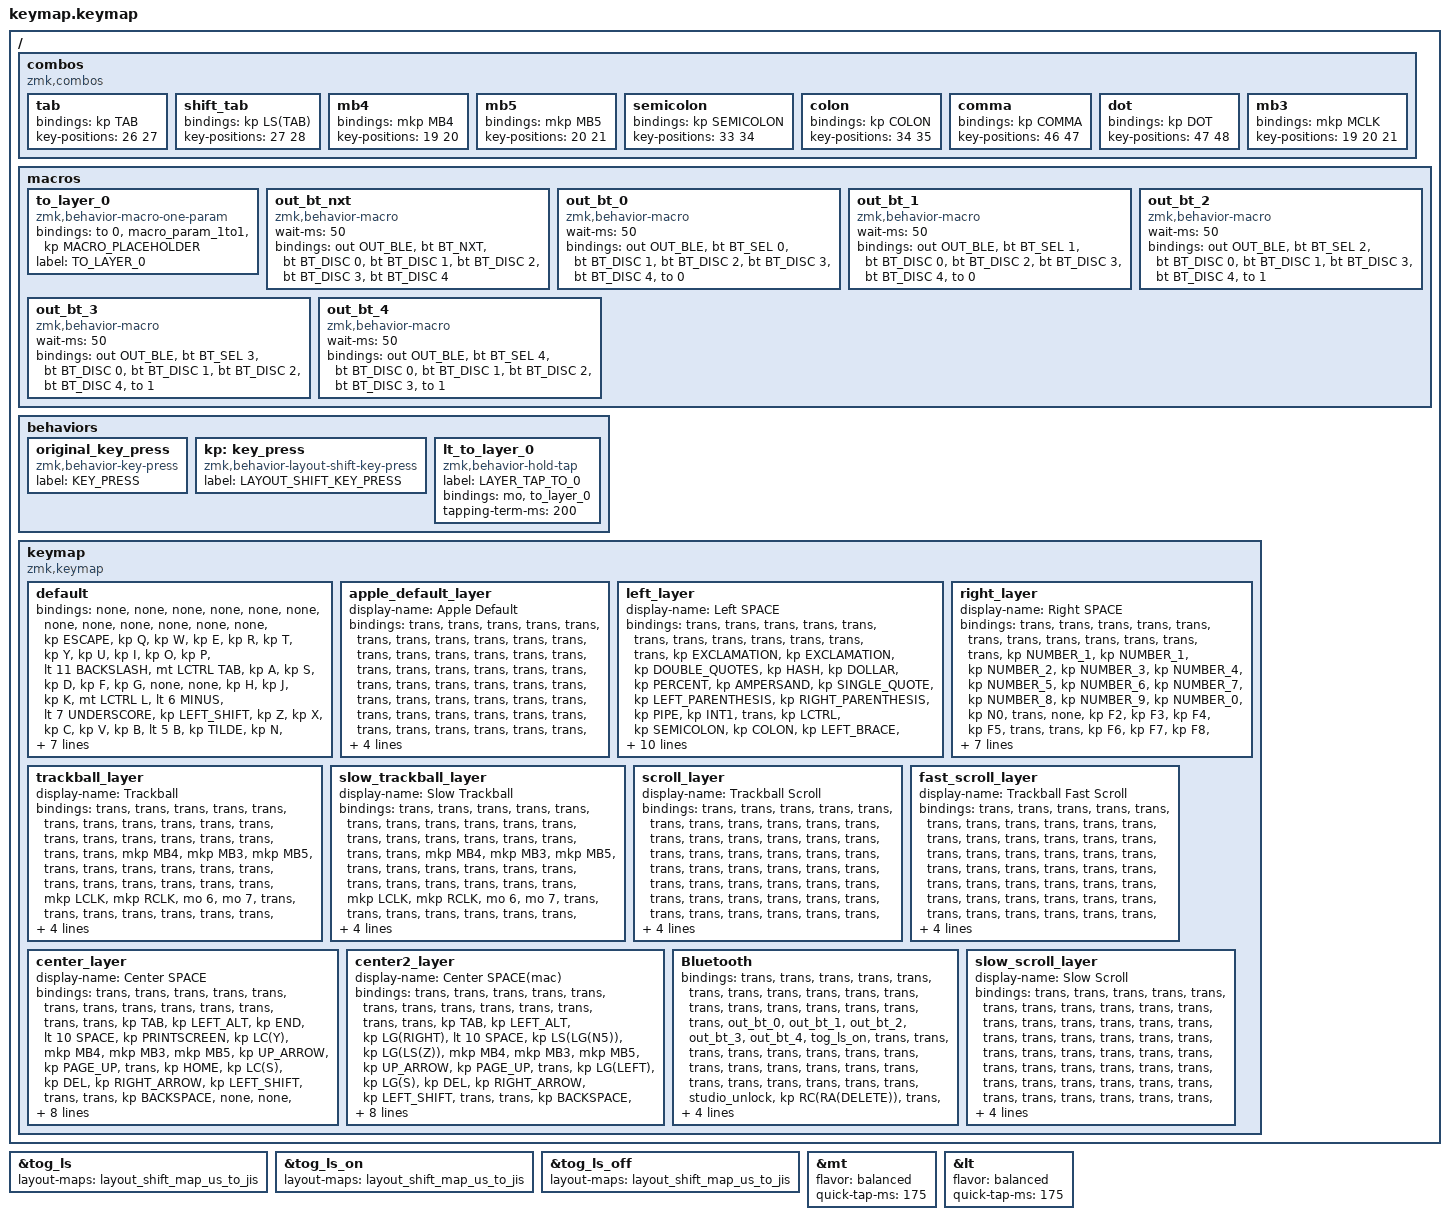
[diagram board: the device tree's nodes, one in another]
// Layer definitions

#include "layers.dtsi"

// ZMK Layout Shiftモジュール(https://github.com/kot149/zmk-layout-shift/blob/v2/README_ja.md)を使う
// US配列のキーコードをJIS配列OS向けに変換する(&kpの上書きはKeymapEditor対策としてbehaviors内で直接定義)

#include <layout_shift.dtsi>
#include <behaviors.dtsi>
#include <dt-bindings/zmk/bt.h>
#include <dt-bindings/zmk/keys.h>
#include <dt-bindings/zmk/outputs.h>
#include <dt-bindings/zmk/pointing.h>

&tog_ls { layout-maps = <&layout_shift_map_us_to_jis>; };
&tog_ls_on { layout-maps = <&layout_shift_map_us_to_jis>; };
&tog_ls_off { layout-maps = <&layout_shift_map_us_to_jis>; };

&mt {
    flavor = "balanced";
    quick-tap-ms = <175>;
};

&lt {
    flavor = "balanced";
    quick-tap-ms = <175>;
};

/ {
    combos {
        compatible = "zmk,combos";

        tab {
            bindings = <&kp TAB>;
            key-positions = <26 27>;
        };

        shift_tab {
            bindings = <&kp LS(TAB)>;
            key-positions = <27 28>;
        };

        mb4 {
            bindings = <&mkp MB4>;
            key-positions = <19 20>;
        };

        mb5 {
            bindings = <&mkp MB5>;
            key-positions = <20 21>;
        };

        semicolon {
            bindings = <&kp SEMICOLON>;
            key-positions = <33 34>;
        };

        colon {
            bindings = <&kp COLON>;
            key-positions = <34 35>;
        };

        comma {
            bindings = <&kp COMMA>;
            key-positions = <46 47>;
        };

        dot {
            bindings = <&kp DOT>;
            key-positions = <47 48>;
        };

        mb3 {
            bindings = <&mkp MCLK>;
            key-positions = <19 20 21>;
        };
    };

    macros {
        to_layer_0: to_layer_0 {
            compatible = "zmk,behavior-macro-one-param";
            #binding-cells = <1>;
            bindings = <&to 0 &macro_param_1to1 &kp MACRO_PLACEHOLDER>;
            label = "TO_LAYER_0";
        };

        // Disconnect from all once for reliable connection to selected profile.
        // ZMK automatically reconnects to current profile right after disconnection.

        out_bt_nxt: out_bt_nxt {
            compatible = "zmk,behavior-macro";
            #binding-cells = <0>;
            wait-ms = <50>;
            bindings = <&out OUT_BLE &bt BT_NXT &bt BT_DISC 0 &bt BT_DISC 1 &bt BT_DISC 2 &bt BT_DISC 3 &bt BT_DISC 4>;
        };

        // Select specific BT device (0-4), disconnect others, and switch to the
        // default layer matching that device's OS (0-1: Windows, 2-4: Apple)

        out_bt_0: out_bt_0 {
            compatible = "zmk,behavior-macro";
            #binding-cells = <0>;
            wait-ms = <50>;
            bindings = <&out OUT_BLE &bt BT_SEL 0 &bt BT_DISC 1 &bt BT_DISC 2 &bt BT_DISC 3 &bt BT_DISC 4 &to 0>;
        };

        out_bt_1: out_bt_1 {
            compatible = "zmk,behavior-macro";
            #binding-cells = <0>;
            wait-ms = <50>;
            bindings = <&out OUT_BLE &bt BT_SEL 1 &bt BT_DISC 0 &bt BT_DISC 2 &bt BT_DISC 3 &bt BT_DISC 4 &to 0>;
        };

        out_bt_2: out_bt_2 {
            compatible = "zmk,behavior-macro";
            #binding-cells = <0>;
            wait-ms = <50>;
            bindings = <&out OUT_BLE &bt BT_SEL 2 &bt BT_DISC 0 &bt BT_DISC 1 &bt BT_DISC 3 &bt BT_DISC 4 &to 1>;
        };

        out_bt_3: out_bt_3 {
            compatible = "zmk,behavior-macro";
            #binding-cells = <0>;
            wait-ms = <50>;
            bindings = <&out OUT_BLE &bt BT_SEL 3 &bt BT_DISC 0 &bt BT_DISC 1 &bt BT_DISC 2 &bt BT_DISC 4 &to 1>;
        };

        out_bt_4: out_bt_4 {
            compatible = "zmk,behavior-macro";
            #binding-cells = <0>;
            wait-ms = <50>;
            bindings = <&out OUT_BLE &bt BT_SEL 4 &bt BT_DISC 0 &bt BT_DISC 1 &bt BT_DISC 2 &bt BT_DISC 3 &to 1>;
        };
    };

    behaviors {
        // for ZMK Layout Shiftモジュール-S
        // KeymapEditor対策で&kpを定義しておく
        // Keep the original key_press behavior for ZMK core components

        original_key_press: original_key_press {
            compatible = "zmk,behavior-key-press";
            #binding-cells = <1>;
            label = "KEY_PRESS";
        };

        // Override the existing &kp behavior to use our custom implementation

        kp: key_press {
            compatible = "zmk,behavior-layout-shift-key-press";
            #binding-cells = <1>;
            label = "LAYOUT_SHIFT_KEY_PRESS";
        };

        // for ZMK Layout Shiftモジュール-ENTER

        lt_to_layer_0: lt_to_layer_0 {
            compatible = "zmk,behavior-hold-tap";
            label = "LAYER_TAP_TO_0";
            bindings = <&mo>, <&to_layer_0>;

            #binding-cells = <2>;
            tapping-term-ms = <200>;
        };
    };

    keymap {
        compatible = "zmk,keymap";

        default {
            bindings = <
&none           &none      &none         &none         &none                  &none                                                        &none      &none  &none      &none         &none                  &none
&kp ESCAPE      &kp Q      &kp W         &kp E         &kp R          &kp T                                        &kp Y      &kp U  &kp I      &kp O         &kp P                  &lt 11 BACKSLASH
&mt LCTRL TAB   &kp A      &kp S         &kp D         &kp F          &kp G          &none          &none          &kp H      &kp J  &kp K      &mt LCTRL L   &lt 6 MINUS            &lt 7 UNDERSCORE
&kp LEFT_SHIFT  &kp Z      &kp X         &kp C         &kp V          &kp B          &lt 5 B        &kp TILDE      &kp N      &kp M  &mkp LCLK  &mkp RCLK     &mt RIGHT_SHIFT SLASH  &kp RIGHT_SHIFT
&kp LCTRL       &kp LCTRL  &kp LEFT_WIN  &kp LEFT_ALT  &lt 2 INT_HENKAN  &lt 8 SPACE  &lt 3 INT_MUHENKAN  &kp BACKSPACE  &kp ENTER  &none  &none      &kp QUESTION  &kp QUESTION           &kp RCTRL
            >;
        };

        apple_default_layer {
            display-name = "Apple Default";
            bindings = <
&trans  &trans  &trans  &trans        &trans      &trans                             &trans  &trans  &trans  &trans  &trans  &trans
&trans  &trans  &trans  &trans        &trans      &trans                             &trans  &trans  &trans  &trans  &trans  &trans
&trans  &trans  &trans  &trans        &trans      &trans  &trans             &trans  &trans  &trans  &trans  &trans  &trans  &trans
&trans  &trans  &trans  &trans        &trans      &trans  &trans             &trans  &trans  &trans  &trans  &trans  &trans  &trans
&trans  &trans  &trans  &kp LEFT_GUI  &lt 2 LANGUAGE_1  &lt 9 SPACE  &lt 3 LANGUAGE_2  &trans  &trans  &trans  &trans  &trans  &trans  &trans
            >;
        };

        left_layer {
            display-name = "Left SPACE";
            bindings = <
&trans           &trans           &trans              &trans        &trans           &trans                                           &trans            &trans        &trans           &trans            &trans        &trans
&kp EXCLAMATION  &kp EXCLAMATION  &kp DOUBLE_QUOTES   &kp HASH      &kp DOLLAR       &kp PERCENT                                      &kp AMPERSAND     &kp SINGLE_QUOTE  &kp LEFT_PARENTHESIS  &kp RIGHT_PARENTHESIS  &kp PIPE      &kp INT1
&trans           &kp LCTRL        &kp SEMICOLON       &kp COLON     &kp LEFT_BRACE   &kp RIGHT_BRACE  &trans         &trans           &kp CARET         &kp AT            &kp LEFT_BRACKET      &kp RIGHT_BRACKET      &kp EQUAL     &kp EQUAL
&kp EQUAL        &trans           &mt LEFT_SHIFT TAB  &kp PLUS      &kp ASTERISK     &kp TILDE      &kp PRINTSCREEN  &kp GRAVE        &kp SEMICOLON     &kp COLON         &kp LESS_THAN         &kp GREATER_THAN       &kp TILDE     &kp RIGHT_SHIFT
&trans           &trans           &trans              &trans        &trans           &trans         &trans           &kp RCTRL        &trans            &trans        &trans           &trans            &trans        &trans
            >;
        };

        right_layer {
            display-name = "Right SPACE";
            bindings = <
&trans        &trans        &trans        &trans        &trans           &trans                             &trans        &trans           &trans        &trans        &trans             &trans
&kp NUMBER_1  &kp NUMBER_1  &kp NUMBER_2  &kp NUMBER_3  &kp NUMBER_4     &kp NUMBER_5                       &kp NUMBER_6  &kp NUMBER_7     &kp NUMBER_8  &kp NUMBER_9  &kp NUMBER_0       &kp N0
&trans        &none         &kp F2        &kp F3        &kp F4           &kp F5        &trans  &trans     &kp F6        &kp F7           &kp F8        &kp F9        &kp UNDERSCORE  &trans
&trans        &trans        &trans        &trans        &kp LS(LC(TAB))  &kp LC(TAB)   &trans  &kp CARET  &kp PLUS      &kp ASTERISK     &kp COMMA     &kp PERIOD    &kp SLASH       &trans
&trans        &trans        &trans        &trans        &trans           &trans        &trans  &trans       &trans        &trans           &trans        &trans        &trans             &trans
            >;
        };

        trackball_layer {
            display-name = "Trackball";
            bindings = <
&trans  &trans  &trans  &trans  &trans  &trans                  &trans  &trans    &trans     &trans     &trans        &trans
&trans  &trans  &trans  &trans  &trans  &trans                  &trans  &mkp MB4  &mkp MB3   &mkp MB5   &trans        &trans
&trans  &trans  &trans  &trans  &trans  &trans  &trans  &trans  &trans  &trans    &mkp LCLK  &mkp RCLK  &mo 6  &mo 7
&trans  &trans  &trans  &trans  &trans  &trans  &trans  &trans  &trans  &trans    &mkp LCLK  &mkp RCLK  &trans        &trans
&trans  &trans  &trans  &trans  &trans  &trans  &trans  &trans  &trans  &trans    &trans     &trans     &trans        &trans
            >;
        };

        slow_trackball_layer {
            display-name = "Slow Trackball";
            bindings = <
&trans  &trans  &trans  &trans  &trans  &trans                  &trans  &trans    &trans     &trans     &trans        &trans
&trans  &trans  &trans  &trans  &trans  &trans                  &trans  &mkp MB4  &mkp MB3   &mkp MB5   &trans        &trans
&trans  &trans  &trans  &trans  &trans  &trans  &trans  &trans  &trans  &trans    &mkp LCLK  &mkp RCLK  &mo 6  &mo 7
&trans  &trans  &trans  &trans  &trans  &trans  &trans  &trans  &trans  &trans    &mkp LCLK  &mkp RCLK  &trans        &trans
&trans  &trans  &trans  &trans  &trans  &trans  &trans  &trans  &trans  &trans    &trans     &trans     &trans        &trans
            >;
        };

        scroll_layer {
            display-name = "Trackball Scroll";
            bindings = <
&trans  &trans  &trans  &trans  &trans  &trans                  &trans  &trans  &trans  &trans  &trans  &trans
&trans  &trans  &trans  &trans  &trans  &trans                  &trans  &trans  &trans  &trans  &trans  &trans
&trans  &trans  &trans  &trans  &trans  &trans  &trans  &trans  &trans  &trans  &trans  &trans  &trans  &trans
&trans  &trans  &trans  &trans  &trans  &trans  &trans  &trans  &trans  &trans  &trans  &trans  &trans  &trans
&trans  &trans  &trans  &trans  &trans  &trans  &trans  &trans  &trans  &trans  &trans  &trans  &trans  &trans
            >;
        };

        fast_scroll_layer {
            display-name = "Trackball Fast Scroll";
            bindings = <
&trans  &trans  &trans  &trans  &trans  &trans                  &trans  &trans  &trans  &trans  &trans  &trans
&trans  &trans  &trans  &trans  &trans  &trans                  &trans  &trans  &trans  &trans  &trans  &trans
&trans  &trans  &trans  &trans  &trans  &trans  &trans  &trans  &trans  &trans  &trans  &trans  &trans  &trans
&trans  &trans  &trans  &trans  &trans  &trans  &trans  &trans  &trans  &trans  &trans  &trans  &trans  &trans
&trans  &trans  &trans  &trans  &trans  &trans  &trans  &trans  &trans  &trans  &trans  &trans  &trans  &trans
            >;
        };

        center_layer {
            display-name = "Center SPACE";
            bindings = <
&trans          &trans     &trans        &trans     &trans           &trans                                  &trans          &trans    &trans     &trans     &trans        &trans
&trans          &kp TAB    &kp LEFT_ALT  &kp END    &lt 10 SPACE   &kp PRINTSCREEN                         &kp LC(Y)       &mkp MB4  &mkp MB3   &mkp MB5   &kp UP_ARROW  &kp PAGE_UP
&trans          &kp HOME   &kp LC(S)     &kp DEL    &kp RIGHT_ARROW  &kp LEFT_SHIFT   &trans  &trans         &kp BACKSPACE   &none     &none      &mkp LCLK  &mkp RCLK     &kp PAGE_DOWN
&kp LEFT_SHIFT  &kp LC(Z)  &kp LC(X)     &kp LC(C)  &kp LC(V)        &kp LEFT_ARROW   &trans  &kp PAGE_DOWN  &kp DOWN_ARROW  &trans    &mkp LCLK  &mkp RCLK  &kp ENTER     &trans
&trans          &trans     &trans        &trans     &trans           &trans           &trans  &kp RCTRL      &trans          &trans    &trans     &trans     &trans        &trans
            >;
        };

        center2_layer {
            display-name = "Center SPACE(mac)";
            bindings = <
&trans          &trans        &trans        &trans     &trans           &trans                                  &trans          &trans    &trans     &trans     &trans        &trans
&trans          &kp TAB       &kp LEFT_ALT  &kp LG(RIGHT)  &lt 10 SPACE   &kp LS(LG(N5))                    &kp LG(LS(Z))   &mkp MB4  &mkp MB3   &mkp MB5   &kp UP_ARROW  &kp PAGE_UP
&trans          &kp LG(LEFT)  &kp LG(S)     &kp DEL    &kp RIGHT_ARROW  &kp LEFT_SHIFT   &trans  &trans         &kp BACKSPACE   &none     &none      &mkp LCLK  &mkp RCLK     &kp PAGE_DOWN
&kp LEFT_SHIFT  &kp LG(Z)     &kp LG(X)     &kp LG(C)  &kp LG(V)        &kp LEFT_ARROW   &trans  &kp PAGE_DOWN  &kp DOWN_ARROW  &trans    &mkp LCLK  &mkp RCLK  &kp ENTER     &trans
&trans          &trans        &trans        &trans     &trans           &trans           &trans  &kp RCTRL      &trans          &trans    &trans     &trans     &trans        &trans
            >;
        };

        Bluetooth {
            bindings = <
&trans  &trans  &trans  &trans  &trans  &trans                                      &trans     &trans     &trans     &trans     &trans     &trans
&trans  &trans  &trans  &trans  &trans  &trans                                      &out_bt_0  &out_bt_1  &out_bt_2  &out_bt_3  &out_bt_4  &tog_ls_on
&trans  &trans  &trans  &trans  &trans  &trans  &trans          &trans              &trans     &trans     &trans     &trans     &trans     &trans
&trans  &trans  &trans  &trans  &trans  &trans  &studio_unlock  &kp RC(RA(DELETE))  &trans     &trans     &trans     &trans     &trans     &trans
&trans  &trans  &trans  &trans  &trans  &trans  &trans          &trans              &trans     &trans     &trans     &trans     &trans     &trans
            >;
        };

        // 低速スクロールレイヤー（¥キーホールドで起動）
        slow_scroll_layer {
            display-name = "Slow Scroll";
            bindings = <
&trans  &trans  &trans  &trans  &trans  &trans                  &trans  &trans  &trans  &trans  &trans  &trans
&trans  &trans  &trans  &trans  &trans  &trans                  &trans  &trans  &trans  &trans  &trans  &trans
&trans  &trans  &trans  &trans  &trans  &trans  &trans  &trans  &trans  &trans  &trans  &trans  &trans  &trans
&trans  &trans  &trans  &trans  &trans  &trans  &trans  &trans  &trans  &trans  &trans  &trans  &trans  &trans
&trans  &trans  &trans  &trans  &trans  &trans  &trans  &trans  &trans  &trans  &trans  &trans  &trans  &trans
            >;
        };
    };
};
